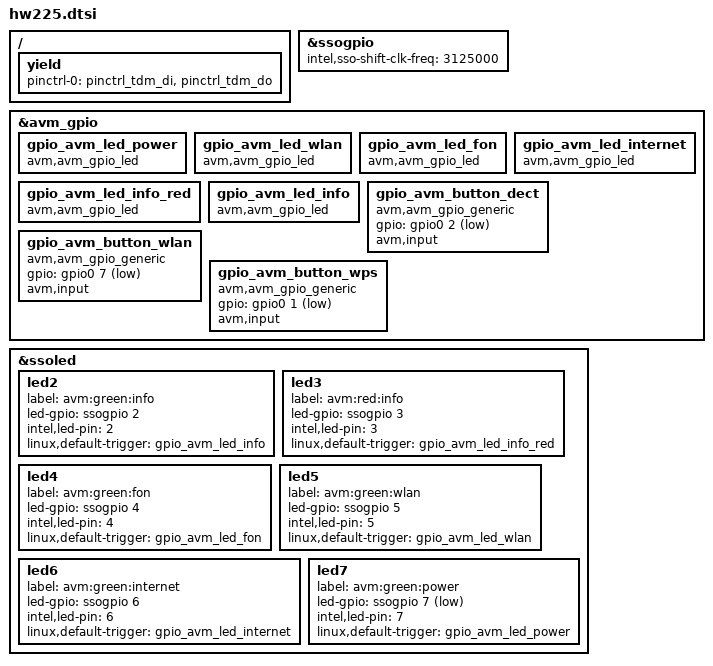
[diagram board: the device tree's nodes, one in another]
#include "grx550_common.dtsi"
#include "vrx318.dtsi"

/ {
	yield {
		/* kein clkout */
		pinctrl-names = "default";
		pinctrl-0 = <&pinctrl_tdm_di &pinctrl_tdm_do>;
	};
};

&ssogpio {
	intel,sso-shift-clk-freq = <3125000>;
};

&avm_gpio {
	/delete-node/ gpio_avm_piglet_noemif_te_found;

	gpio_avm_led_power {
		compatible = "avm,avm_gpio_led";
	};
	gpio_avm_led_wlan {
		compatible = "avm,avm_gpio_led";
	};
	gpio_avm_led_fon {
		compatible = "avm,avm_gpio_led";
	};
	gpio_avm_led_internet {
		compatible = "avm,avm_gpio_led";
	};
	gpio_avm_led_info_red {
		compatible = "avm,avm_gpio_led";
	};
	gpio_avm_led_info {
		compatible = "avm,avm_gpio_led";
	};
	gpio_avm_button_dect {
		compatible = "avm,avm_gpio_generic";
		gpio = <&gpio0 2 GPIO_ACTIVE_LOW>;
		avm,input;
	};
	gpio_avm_button_wlan {
		compatible = "avm,avm_gpio_generic";
		gpio = <&gpio0 7 GPIO_ACTIVE_LOW>;
		avm,input;
	};
	gpio_avm_button_wps {
		compatible = "avm,avm_gpio_generic";
		gpio = <&gpio0 1 GPIO_ACTIVE_LOW>;
		avm,input;
	};
};

&ssoled {
	status = "okay";

	led2 {
		label = "avm:green:info";
		led-gpio = <&ssogpio 2 GPIO_ACTIVE_HIGH>;
		intel,led-pin = <2>;
		linux,default-trigger = "gpio_avm_led_info";
	};
	led3 {
		label = "avm:red:info";
		led-gpio = <&ssogpio 3 GPIO_ACTIVE_HIGH>;
		intel,led-pin = <3>;
		linux,default-trigger = "gpio_avm_led_info_red";
	};
	led4 {
		label = "avm:green:fon";
		led-gpio = <&ssogpio 4 GPIO_ACTIVE_HIGH>;
		intel,led-pin = <4>;
		linux,default-trigger = "gpio_avm_led_fon";
	};
	led5 {
		label = "avm:green:wlan";
		led-gpio = <&ssogpio 5 GPIO_ACTIVE_HIGH>;
		intel,led-pin = <5>;
		linux,default-trigger = "gpio_avm_led_wlan";
	};
	led6 {
		label = "avm:green:internet";
		led-gpio = <&ssogpio 6 GPIO_ACTIVE_HIGH>;
		intel,led-pin = <6>;
		linux,default-trigger = "gpio_avm_led_internet";
	};
	led7 {
		label = "avm:green:power";
		led-gpio = <&ssogpio 7 GPIO_ACTIVE_LOW>;
		intel,led-pin = <7>;
		linux,default-trigger = "gpio_avm_led_power";
	};
};
